# PosMaskDim register map
Vendor: ARM Ltd.; Series: ARM Cortex M3; File version: 1.0
Test device for dim fields in pos/mask generation.
CPU: CM3 r2p1, little endian, MPU, no FPU, VTOR, 3 interrupt priority bits
Registers are 32-bit, read-write, reset 0x0 unless marked. A register's access mark holds for its fields unless they carry their own. Offsets are from the block's base; lines under a group give offsets from that group; [hi:lo] are bit positions; {n}, {i} and the like mark numbered series; 'fields as' and 'values as' point back to an identical list; <NAME> marks a mode.

## Memory map
0x40000000 TIM size 0x400 — Timer.

## TIM — Timer.
Base 0x40000000
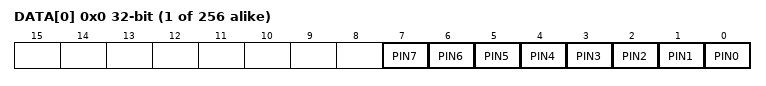
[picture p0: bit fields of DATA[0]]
{0x0+4i} DATA[{i}] (i=0..255)
  [n] PIN{n} (n=0..7) — Pin data.
    0=Disabled (Channel disabled.); 1=Enabled (Channel enabled.)
